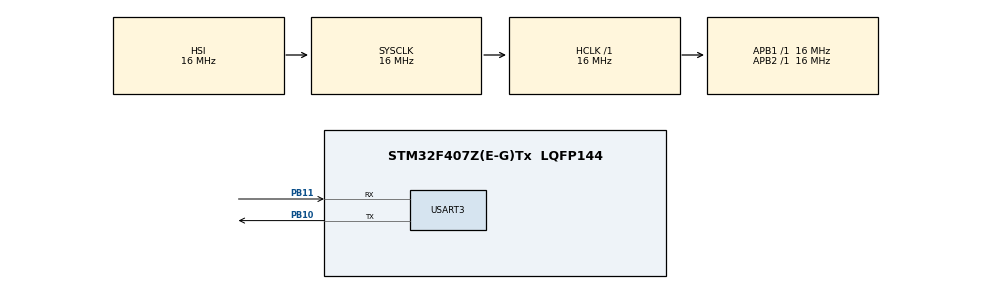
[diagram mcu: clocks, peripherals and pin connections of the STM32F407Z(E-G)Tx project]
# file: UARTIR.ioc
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Mcu.Family=STM32F4
Mcu.Name=STM32F407Z(E-G)Tx
Mcu.Package=LQFP144
NVIC.PriorityGroup=NVIC_PRIORITYGROUP_4
NVIC.USART3_IRQn=true\:0\:0\:false\:false\:true\:true\:true\:true
PA13.Mode=Serial_Wire
PA13.Signal=SYS_JTMS-SWDIO
PA14.Mode=Serial_Wire
PA14.Signal=SYS_JTCK-SWCLK
PB10.Mode=Asynchronous
PB10.Signal=USART3_TX
PB11.Mode=Asynchronous
PB11.Signal=USART3_RX
ProjectManager.HeapSize=0x200
ProjectManager.StackSize=0x400
ProjectManager.TargetToolchain=STM32CubeIDE
RCC.AHBFreq_Value=16000000
RCC.APB1Freq_Value=16000000
RCC.APB2Freq_Value=16000000
RCC.CortexFreq_Value=16000000
RCC.HSE_VALUE=25000000
RCC.HSI_VALUE=16000000
RCC.LSE_VALUE=32768
RCC.SYSCLKFreq_VALUE=16000000
RCC.VCOOutputFreq_Value=192000000
USART3.VirtualMode=VM_ASYNC
board=custom

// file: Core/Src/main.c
/* USER CODE BEGIN Header */
/**
  ******************************************************************************
  * @file           : main.c
  * @brief          : Main program body
  ******************************************************************************
  * @attention
  *
  * Copyright (c) 2024 STMicroelectronics.
  * All rights reserved.
  *
  * This software is licensed under terms that can be found in the LICENSE file
  * in the root directory of this software component.
  * If no LICENSE file comes with this software, it is provided AS-IS.
  *
  ******************************************************************************
  */
/* USER CODE END Header */
#include "main.h"
#include "usart.h"
#include "gpio.h"

/* USER CODE BEGIN PV */
#ifdef __GNUC__
#define PUTCHAR_PROTOTYPE int __io_putchar(int ch)
#else
#define PUTCHAR_PROTOTYPE int fputc(int ch, FILE *f)
#endif
  PUTCHAR_PROTOTYPE
  {
    HAL_UART_Transmit(&huart3 , (uint8_t *)&ch, 1, 0xFFFF);
    return ch;
  }
/* USER CODE END PV */

void SystemClock_Config(void);

/* USER CODE BEGIN 0 */
uint8_t rx_buffer = 0;
void HAL_UART_RxCpltCallback(UART_HandleTypeDef *huart)
{
  if (huart->Instance == USART3)
  {
    // 在此处处理接收到的数�?
    HAL_UART_Transmit(&huart3, &rx_buffer, 1, HAL_MAX_DELAY);
    // 重新启动 UART 接收中断模式
    HAL_UART_Receive_IT(&huart3, &rx_buffer, 1);
  }
}
/* USER CODE END 0 */

int main(void)
{

  /* MCU Configuration--------------------------------------------------------*/

  /* Reset of all peripherals, Initializes the Flash interface and the Systick. */
  HAL_Init();

  /* Configure the system clock */
  SystemClock_Config();

  /* Initialize all configured peripherals */
  MX_GPIO_Init();
  MX_USART3_UART_Init();
  /* USER CODE BEGIN 2 */
    HAL_UART_Receive_IT(&huart3, &rx_buffer, 1);  // 启动 UART 接收中断模式

  /* USER CODE END 2 */

  /* Infinite loop */
  /* USER CODE BEGIN WHILE */
  while (1)
  {
      printf("1 \r\n");
    HAL_Delay(1000);
    /* USER CODE END WHILE */

  }
}

void SystemClock_Config(void)
{
  RCC_OscInitTypeDef RCC_OscInitStruct = {0};
  RCC_ClkInitTypeDef RCC_ClkInitStruct = {0};

  /** Configure the main internal regulator output voltage
  */
  __HAL_RCC_PWR_CLK_ENABLE();
  __HAL_PWR_VOLTAGESCALING_CONFIG(PWR_REGULATOR_VOLTAGE_SCALE1);

  /** Initializes the RCC Oscillators according to the specified parameters
  * in the RCC_OscInitTypeDef structure.
  */
  RCC_OscInitStruct.OscillatorType = RCC_OSCILLATORTYPE_HSI;
  RCC_OscInitStruct.HSIState = RCC_HSI_ON;
  RCC_OscInitStruct.HSICalibrationValue = RCC_HSICALIBRATION_DEFAULT;
  RCC_OscInitStruct.PLL.PLLState = RCC_PLL_NONE;
  if (HAL_RCC_OscConfig(&RCC_OscInitStruct) != HAL_OK)
  {
    Error_Handler();
  }

  /** Initializes the CPU, AHB and APB buses clocks
  */
  RCC_ClkInitStruct.ClockType = RCC_CLOCKTYPE_HCLK|RCC_CLOCKTYPE_SYSCLK
                              |RCC_CLOCKTYPE_PCLK1|RCC_CLOCKTYPE_PCLK2;
  RCC_ClkInitStruct.SYSCLKSource = RCC_SYSCLKSOURCE_HSI;
  RCC_ClkInitStruct.AHBCLKDivider = RCC_SYSCLK_DIV1;
  RCC_ClkInitStruct.APB1CLKDivider = RCC_HCLK_DIV1;
  RCC_ClkInitStruct.APB2CLKDivider = RCC_HCLK_DIV1;

  if (HAL_RCC_ClockConfig(&RCC_ClkInitStruct, FLASH_LATENCY_0) != HAL_OK)
  {
    Error_Handler();
  }
}

void Error_Handler(void)
{
  __disable_irq();
  while (1)
  {
  }
}
